CM_ "IMPORT subaru_global_2017.dbc";

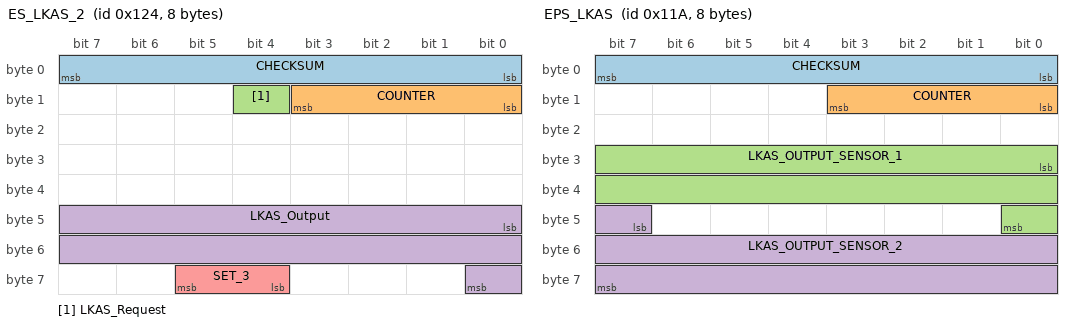
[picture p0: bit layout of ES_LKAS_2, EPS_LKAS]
BO_ 292 ES_LKAS_2: 8 XXX
 SG_ CHECKSUM : 0|8@1+ (1,0) [0|1] "" XXX
 SG_ COUNTER : 8|4@1+ (1,0) [0|1] "" XXX
 SG_ LKAS_Request : 12|1@1+ (1,0) [0|1] "" XXX
 SG_ LKAS_Output : 40|17@1- (-1,0) [0|1] "" XXX
 SG_ SET_3 : 60|2@1+ (1,0) [0|1] "" XXX

BO_ 282 EPS_LKAS: 8 XXX
 SG_ CHECKSUM : 0|8@1+ (1,0) [0|1] "" XXX
 SG_ COUNTER : 8|4@1+ (1,0) [0|1] "" XXX
 SG_ LKAS_OUTPUT_SENSOR_1 : 24|17@1- (1,0) [0|1] "" XXX
 SG_ LKAS_OUTPUT_SENSOR_2 : 47|17@1- (1,0) [0|1] "" XXX
